AUTOSAR XML (schema 4-0-3)
package /AppSwComponent_Dcm/SwComponentType
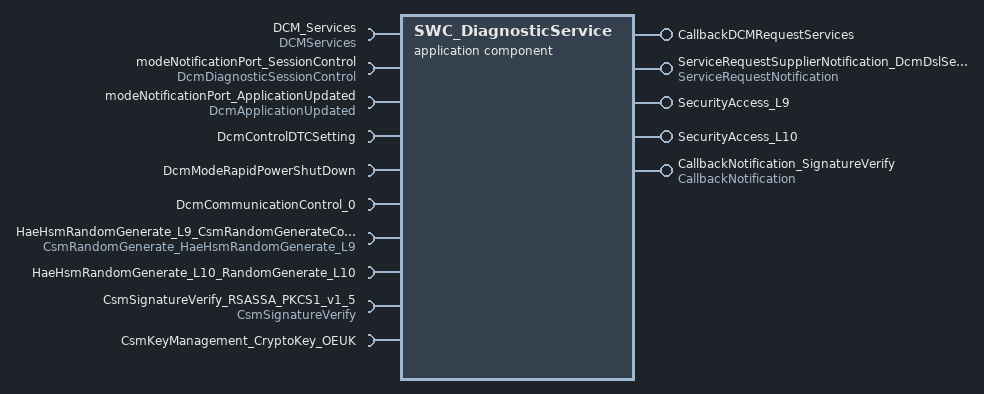
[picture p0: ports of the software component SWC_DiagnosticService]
  application sw component type SWC_DiagnosticService
    provide port CallbackDCMRequestServices: provided-com-specs=[{operation=StopProtocol, queue-length=1}, {operation=StartProtocol, queue-length=1}], provided-interface=CallbackDCMRequestServices
    require port DCM_Services: required-com-specs=[GetActiveProtocol, GetSecurityLevel, ResetToDefaultSession, GetSesCtrlType], required-interface=DCMServices
    provide port ServiceRequestSupplierNotification_DcmDslServiceRequestSupplierNotification0: provided-com-specs=[{operation=Indication, queue-length=1}, {operation=Confirmation, queue-length=1}], provided-interface=ServiceRequestNotification
    5 x require port:
      modeNotificationPort_SessionControl: mode-switch-receiver-com-spec{enhanced-mode-api=true, mode-group=DcmDiagnosticSessionControl, supports-asynchronous-mode-switch=true}, required-interface=DcmDiagnosticSessionControl
      modeNotificationPort_ApplicationUpdated: mode-switch-receiver-com-spec{enhanced-mode-api=true, mode-group=DcmApplicationUpdated, supports-asynchronous-mode-switch=true}, required-interface=DcmApplicationUpdated
      DcmControlDTCSetting: mode-switch-receiver-com-spec{enhanced-mode-api=true, mode-group=DcmControlDTCSetting, supports-asynchronous-mode-switch=true}, required-interface=DcmControlDTCSetting
      DcmModeRapidPowerShutDown: mode-switch-receiver-com-spec{enhanced-mode-api=true, mode-group=DcmModeRapidPowerShutDown, supports-asynchronous-mode-switch=true}, required-interface=DcmModeRapidPowerShutDown
      DcmCommunicationControl_0: mode-switch-receiver-com-spec{enhanced-mode-api=true, mode-group=DcmCommunicationControl_0, supports-asynchronous-mode-switch=true}, required-interface=DcmCommunicationControl_0
    provide port SecurityAccess_L9: provided-com-specs=[{operation=CompareKey, queue-length=1}, {operation=GetSeed, queue-length=1}], provided-interface=SecurityAccess_L9
    provide port SecurityAccess_L10: provided-com-specs=[{operation=GetSeed, queue-length=1}, {operation=CompareKey, queue-length=1}], provided-interface=SecurityAccess_L10
    require port HaeHsmRandomGenerate_L9_CsmRandomGenerateConfig: client-com-spec=RandomGenerate, required-interface=CsmRandomGenerate_HaeHsmRandomGenerate_L9
    require port HaeHsmRandomGenerate_L10_RandomGenerate_L10: client-com-spec=RandomGenerate, required-interface=HaeHsmRandomGenerate_L10_RandomGenerate_L10
    provide port CallbackNotification_SignatureVerify: server-com-spec{operation=CallbackNotification, queue-length=1}, provided-interface=CallbackNotification
    require port CsmSignatureVerify_RSASSA_PKCS1_v1_5: client-com-spec=SignatureVerify, required-interface=CsmSignatureVerify
    require port CsmKeyManagement_CryptoKey_OEUK: required-com-specs=[KeyElementSet, KeySetValid], required-interface=CsmKeyManagement_CryptoKey_OEUK
    behavior InternalBehaviors_DiagnosticService: data-type-mapping=DcmApplicationUpdated
      4 x operation invoked event:
        OIE_CallbackDCMRequestServices_StopProtocol: start-on-event=CallbackDCMRequestServices_StopProtocol, operation=CallbackDCMRequestServices.StopProtocol
        OIE_CallbackDCMRequestServices_StartProtocol: start-on-event=CallbackDCMRequestServices_StartProtocol, operation=CallbackDCMRequestServices.StartProtocol
        OIE_ServiceRequestSupplierNotification_Indication: start-on-event=ServiceRequestSupplierNotification_Indication, operation=ServiceRequestSupplierNotification_DcmDslServiceRequestSupplierNotification0.Indication
        OIE_ServiceRequestSupplierNotification_Confirmation: start-on-event=ServiceRequestSupplierNotification_Confirmation, operation=ServiceRequestSupplierNotification_DcmDslServiceRequestSupplierNotification0.Confirmation
      4 x swc mode switch event, all with activation=ON-ENTRY:
        SMSE_Entry_DiagnosticSessionControlNotification_modeNotificationPort_SessionControl_DcmDiagnosticSessionControl_DCM_DEFAULT_SESSION: start-on-event=DiagnosticSessionControlNotification, mode=modeNotificationPort_SessionControl.DcmDiagnosticSessionControl.DCM_DEFAULT_SESSION
        SMSE_Entry_DiagnosticSessionControlNotification_modeNotificationPort_SessionControl_DcmDiagnosticSessionControl_DCM_EXTENDED_DIAGNOSTIC_SESSION: start-on-event=DiagnosticSessionControlNotification, mode=modeNotificationPort_SessionControl.DcmDiagnosticSessionControl.DCM_EXTENDED_DIAGNOSTIC_SESSION
        SMSE_ApplicationUpdatedIndication_modeNotificationPort_ApplicationUpdated_DcmApplicationUpdated_APP_UPDATED: start-on-event=ApplicationUpdatedIndication, mode=modeNotificationPort_ApplicationUpdated.DcmApplicationUpdated.APP_UPDATED
        SMSE_ApplicationUpdatedIndication_modeNotificationPort_ApplicationUpdated_DcmApplicationUpdated_APP_NOT_UPDATED: start-on-event=ApplicationUpdatedIndication, mode=modeNotificationPort_ApplicationUpdated.DcmApplicationUpdated.APP_NOT_UPDATED
      5 x operation invoked event:
        OIE_L9_CompareKey: start-on-event=L9_CompareKey, operation=SecurityAccess_L9.CompareKey
        OIE_L9_GetSeed: start-on-event=L9_GetSeed, operation=SecurityAccess_L9.GetSeed
        OIE_L10_GetSeed_SecurityAccess_L10_GetSeed: start-on-event=L10_GetSeed, operation=SecurityAccess_L10.GetSeed
        OIE_L10_CompareKey_SecurityAccess_L10_CompareKey: start-on-event=L10_CompareKey, operation=SecurityAccess_L10.CompareKey
        OIE_OEUK_AsyncVerifyFinished_CallbackNotification_SignatureVerify_CallbackNotification: start-on-event=OEUK_AsyncVerifyFinished, operation=CallbackNotification_SignatureVerify.CallbackNotification
      13 x runnable:
        CallbackDCMRequestServices_StopProtocol: can-be-invoked-concurrently=true, symbol=AppDcm_StopProtocol
        CallbackDCMRequestServices_StartProtocol: can-be-invoked-concurrently=true, symbol=AppDcm_StartProtocol
        DO_NOT_REMOVE: can-be-invoked-concurrently=true, symbol=AppDcm_Runnable
          4 x sync call:
            SSCP_GetActiveProtocol: operation=DCM_Services.GetActiveProtocol
            SSCP_GetSecurityLevel: operation=DCM_Services.GetSecurityLevel
            SSCP_ResetToDefaultSession: operation=DCM_Services.ResetToDefaultSession
            SSCP_GetSesCtrlType: operation=DCM_Services.GetSesCtrlType
        DID_0100h_0110h_ReadDidData: can-be-invoked-concurrently=true, symbol=AppDcm_ReadDidData_DID_0100h_0110h
        ServiceRequestSupplierNotification_Indication: can-be-invoked-concurrently=true
        ServiceRequestSupplierNotification_Confirmation: can-be-invoked-concurrently=true
        DiagnosticSessionControlNotification: can-be-invoked-concurrently=true, symbol=AppDcm_DiagnosticSessionControlNotification
          mode-access-point mode-group=modeNotificationPort_SessionControl.DcmDiagnosticSessionControl:
            ident MRAP_DiagnosticSessionControlNotification_modeNotificationPort_SessionControl_DcmDiagnosticSessionControl
        ApplicationUpdatedIndication: can-be-invoked-concurrently=true
          mode-access-point mode-group=modeNotificationPort_ApplicationUpdated.DcmApplicationUpdated:
            ident MRAP_ApplicationUpdatedIndication_modeNotificationPort_ApplicationUpdated_DcmApplicationUpdated
        L9_CompareKey: can-be-invoked-concurrently=true, symbol=AppDcm_CompareKey_L9
        L9_GetSeed: can-be-invoked-concurrently=true, symbol=AppDcm_GetSeed_L9
          sync call SSCP_L9_GetSeed_HaeHsmRandomGenerate_L9_CsmRandomGenerateConfig_RandomGenerate: operation=HaeHsmRandomGenerate_L9_CsmRandomGenerateConfig.RandomGenerate
        L10_GetSeed: symbol=AppDcm_GetSeed_L10
          sync call SSCP_L10_GetSeed_HaeHsmRandomGenerate_L10_RandomGenerate_L10_RandomGenerate: operation=HaeHsmRandomGenerate_L10_RandomGenerate_L10.RandomGenerate
        L10_CompareKey: symbol=AppDcm_CompareKey_L10
          sync call SSCP_L10_CompareKey_CsmKeyManagement_CryptoKey_OEUK_KeyElementSet: operation=CsmKeyManagement_CryptoKey_OEUK.KeyElementSet
          sync call SSCP_L10_CompareKey_CsmKeyManagement_CryptoKey_OEUK_KeySetValid: operation=CsmKeyManagement_CryptoKey_OEUK.KeySetValid
          sync call SSCP_L10_CompareKey_CsmSignatureVerify_RSASSA_PKCS1_v1_5_SignatureVerify: operation=CsmSignatureVerify_RSASSA_PKCS1_v1_5.SignatureVerify
        OEUK_AsyncVerifyFinished: symbol=AppDcm_CompareKey_L10_cbk
      swc service dependency SwcServiceDependency0
        assigned-ports:
          port-prototype=modeNotificationPort_SessionControl, role=Custom
          port-prototype=modeNotificationPort_ApplicationUpdated, role=Custom
          port-prototype=DcmControlDTCSetting, role=Custom
          port-prototype=DcmModeRapidPowerShutDown, role=Custom
          port-prototype=DcmCommunicationControl_0, role=Custom
        service-needs:
          bsw mgr needs BswMgrNeeds
  swc implementation App_Dcm_Implementation: behavior=InternalBehaviors_DiagnosticService
    code-descriptors:
      code Default
